AUTOSAR XML (schema 4-0-3)
standard types defined: UInt32, UInt8
package /AUTOSAR_Platform/DataConstrs
  range DC_UInt8: raw 0..255
package /PATAC/MSM/ComponentTypes
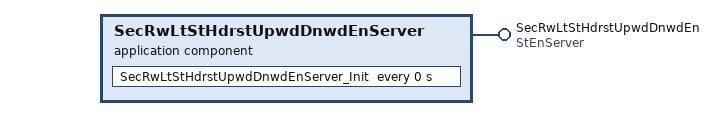
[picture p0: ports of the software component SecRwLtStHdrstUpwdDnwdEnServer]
  application sw component type SecRwLtStHdrstUpwdDnwdEnServer
    provide port SecRwLtStHdrstUpwdDnwdEn: provided-com-specs=[{operation=Clear, queue-length=1}, {operation=Get, queue-length=1}, {operation=Set, queue-length=1}], provided-interface=StEnServer
    behavior SecRwLtStHdrstUpwdDnwdEnServer_InternalBehavior
      operation invoked event OIT_SecRwLtStHdrstUpwdDnwdEn_Clear_SecRwLtStHdrstUpwdDnwdEn_Clear: start-on-event=SecRwLtStHdrstUpwdDnwdEn_Clear, operation=SecRwLtStHdrstUpwdDnwdEn.Clear
      operation invoked event OIT_SecRwLtStHdrstUpwdDnwdEn_Get_SecRwLtStHdrstUpwdDnwdEn_Get: start-on-event=SecRwLtStHdrstUpwdDnwdEn_Get, operation=SecRwLtStHdrstUpwdDnwdEn.Get
      operation invoked event OIT_SecRwLtStHdrstUpwdDnwdEn_Set_SecRwLtStHdrstUpwdDnwdEn_Set: start-on-event=SecRwLtStHdrstUpwdDnwdEn_Set, operation=SecRwLtStHdrstUpwdDnwdEn.Set
      timing event SecRwLtStHdrstUpwdDnwdEnServer_InitEvent: start-on-event=SecRwLtStHdrstUpwdDnwdEnServer_Init, period=0
      4 x runnable:
        SecRwLtStHdrstUpwdDnwdEn_Clear
        SecRwLtStHdrstUpwdDnwdEn_Get
        SecRwLtStHdrstUpwdDnwdEn_Set
        SecRwLtStHdrstUpwdDnwdEnServer_Init
  swc implementation SecRwLtStHdrstUpwdDnwdEnServer_Implementation: behavior=SecRwLtStHdrstUpwdDnwdEnServer_InternalBehavior
    code-descriptors:
      code Default: artifact-descriptors=autosar-engineering-object={short-label=Default, category=SWSRC}
package /PATAC/MSM/ModeAdjust/PortInterface
  client server interface StEnServer
    operation Clear
      arg data: type=UInt8, direction=IN, server-argument-impl-policy=USE-ARGUMENT-TYPE
    operation Get
      arg data: type=UInt32, direction=OUT, server-argument-impl-policy=USE-ARGUMENT-TYPE
    operation Set
      arg data: type=UInt8, direction=IN, server-argument-impl-policy=USE-ARGUMENT-TYPE
